# PIC32MK0512MCF100 device description
Architecture: MIPS; Family: PIC32MK; Series: PIC32MK
Registers are 32-bit, read-write, no defined reset value unless marked. A register's access mark holds for its fields unless they carry their own. Offsets are from the block's base; [hi:lo] are bit positions; {n}, {i} and the like mark numbered series; 'fields as' and 'values as' point back to an identical list.

## JTAG
Instances: JTAG 0x1f801000 in periph_pb1_std
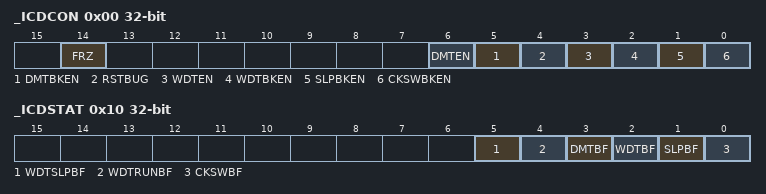
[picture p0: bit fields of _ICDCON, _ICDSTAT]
0x00 _ICDCON
  [14] FRZ, [6] DMTEN, [5] DMTBKEN, [4] RSTBUG, [3] WDTEN, [2] WDTBKEN, [1] SLPBKEN, [0] CKSWBKEN
0x10 _ICDSTAT
  [5] WDTSLPBF, [4] WDTRUNBF, [3] DMTBF, [2] WDTBF, [1] SLPBF, [0] CKSWBF

## OCMP
Instances: OCMP 0x1f824000 in periph_pb2_std
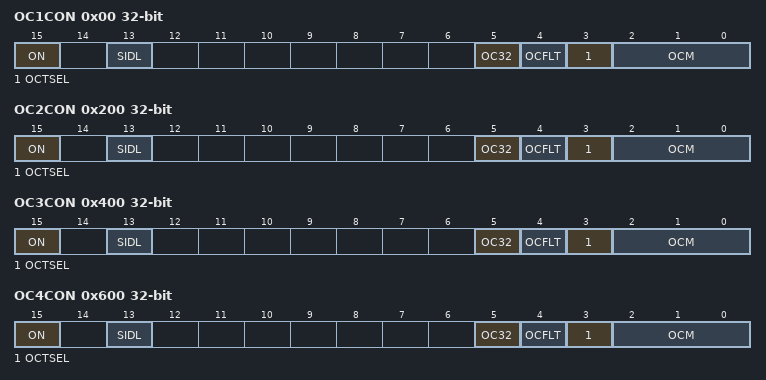
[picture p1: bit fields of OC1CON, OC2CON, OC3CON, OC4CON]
0x00 OC1CON — Output Compare 'x' Control Register
  [15] ON — Output Compare Peripheral On bit
    1=Output Compare peripheral is enabled; 0=Output Compare peripheral is disabled
  [13] SIDL — Stop in Idle Mode bit
    1=Discontinue operation when CPU enters Idle mode; 0=Continue operation in Idle mode
  [5] OC32 — 32-bit Compare Mode bit
    1=OCxR and/or OCxRS<31:0> are used for comparisions to the 32-bit timer source; 0=OCxR and OCxRS<15:0> are used for comparisons to the 16-bit timer source
  [4] OCFLT — PWM Fault Condition Status bit
    1=PWM Fault condition has occurred (cleared in HW only); 0=No PWM Fault condition has occurred
  [3] OCTSEL — Output Compare Timer Select bit
    1=Timery is the clock source for this Output Compare module; 0=Timerx is the clock source for this Output Compare module
  [2:0] OCM — Output Compare Mode Select bits
    7=PWM mode on OCx; Fault pin enabled; 6=PWM mode on OCx; Fault pin diabled; 5=Initialize OCx pin low; generate continious output pulses on OCx pin; 4=Initialize OCx pin low; generate single output pulse on OCx pin; 3=Compare event toggles OCx pin; 2=Initialize OCx pin high; compare event forces OCx pin low; 1=Initialize OCx pin low; compare event forces OCx pin high; 0=Output compare peripheral is disabled but continues to draw current
0x10 OC1R
0x20 OC1RS
0x200 OC2CON — Output Compare 'x' Control Register
  fields as OC1CON
0x210 OC2R
0x220 OC2RS
0x400 OC3CON — Output Compare 'x' Control Register
  fields as OC1CON
0x410 OC3R
0x420 OC3RS
0x600 OC4CON — Output Compare 'x' Control Register
  fields as OC1CON
0x610 OC4R
0x620 OC4RS
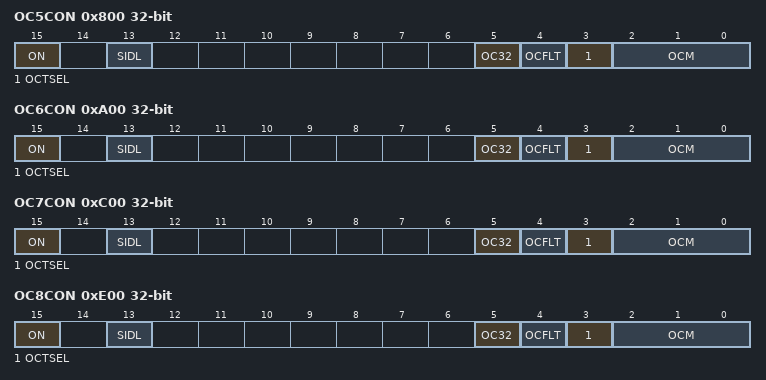
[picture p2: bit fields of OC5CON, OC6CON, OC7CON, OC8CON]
0x800 OC5CON — Output Compare 'x' Control Register
  fields as OC1CON
0x810 OC5R
0x820 OC5RS
0xA00 OC6CON — Output Compare 'x' Control Register
  fields as OC1CON
0xA10 OC6R
0xA20 OC6RS
0xC00 OC7CON — Output Compare 'x' Control Register
  fields as OC1CON
0xC10 OC7R
0xC20 OC7RS
0xE00 OC8CON — Output Compare 'x' Control Register
  fields as OC1CON
0xE10 OC8R
0xE20 OC8RS
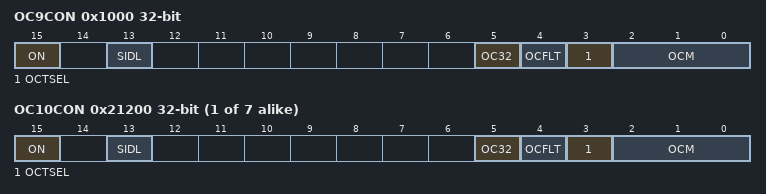
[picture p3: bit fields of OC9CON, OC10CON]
0x1000 OC9CON — Output Compare 'x' Control Register
  fields as OC1CON
0x1010 OC9R
0x1020 OC9RS
{0x1FE00+0x200*i} OC{i}CON (i=10..16) — Output Compare 'x' Control Register
  fields as OC1CON
{0x1FE10+0x200*i} OC{i}R (i=10..16)
{0x1FE20+0x200*i} OC{i}RS (i=10..16)

## PCACHE
Instances: PCACHE 0x1f800800 in periph_pb1_std
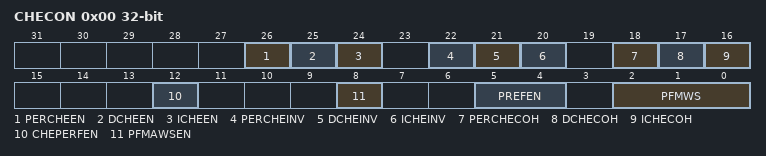
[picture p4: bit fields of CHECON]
0x00 CHECON — Cache Module Control Register
  [26] PERCHEEN — Peripheral Cache Enable bit
    1=Peripheral cache is enabled; 0=Peripheral cache is disabled
  [25] DCHEEN — Data Cache Enable bit
    1=Data cache is enabled; 0=Data cache is disabled
  [24] ICHEEN — Instruction Cache Enable bit
    1=Instruction cache is enabled; 0=Instruction cache is disabled
  [22] PERCHEINV — Peripheral Cache Invalidate bit
    1=Force invalidate cache/invalidate busy; 0=Cache Invalidation follows CHECOH/invalid complete
  [21] DCHEINV — Data Cache Invalidate bit
    values as PERCHEINV
  [20] ICHEINV — Instruction Cache Invalidate bit
    values as PERCHEINV
  [18] PERCHECOH — Peripheral Auto-cache Coherency Control bit
    1=Automatically invalidate cache on a programming event; 0=Do not automatically invalidate cache on a programming event
  [17] DCHECOH — Data Auto-cache Coherency Control bit
    values as PERCHECOH
  [16] ICHECOH — Instruction Auto-cache Coherency Control bit
    values as PERCHECOH
  [12] CHEPERFEN — Cache Performance Counters Enable bit
    1=Performance counters are enabled; 0=Performance counters are disabled
  [8] PFMAWSEN — PFM Address Wait State Enable bit
    1=Add one more Wait State to flash address setup (suggested for higher system clock frequencies); 0=Add no Wait States to the flash address setup (suggested for lower system clock frequencies to achieve higher performance)
  [5:4] PREFEN — Predictive Prefetch Enable bits
    3=Disable predictive prefetch; 2=Disable predictive prefetch; 1=Enable predictive prefetch for CPU instructions only; 0=Disable predictive prefetch
  [2:0] PFMWS — PFM Access Time Defined in Terms of SYSCLK Wait States bits
    7=Seven Wait states; 2=Two Wait states; 1=One Wait state; 0=Zero Wait states
0x20 CHEHIT ro — CACHE Hit Status Register
0x30 CHEMIS ro — CACHE Miss Status Register
